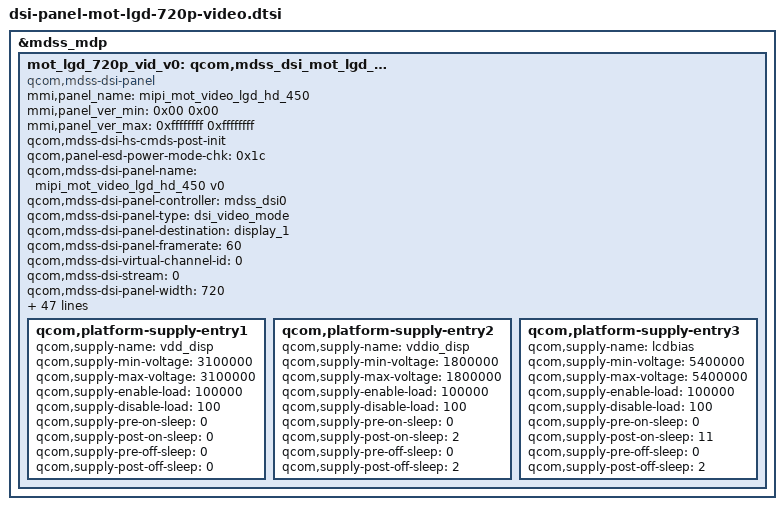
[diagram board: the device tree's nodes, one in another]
/* Copyright (c) 2013, Motorola Mobility LLC. All rights reserved.
 *
 * This program is free software; you can redistribute it and/or modify
 * it under the terms of the GNU General Public License version 2 and
 * only version 2 as published by the Free Software Foundation.
 *
 * This program is distributed in the hope that it will be useful,
 * but WITHOUT ANY WARRANTY; without even the implied warranty of
 * MERCHANTABILITY or FITNESS FOR A PARTICULAR PURPOSE.  See the
 * GNU General Public License for more details.
 */

&mdss_mdp {
	mot_lgd_720p_vid_v0: qcom,mdss_dsi_mot_lgd_720p_video_v0 {
		compatible = "qcom,mdss-dsi-panel";
		status = "ok";

		mmi,panel_name = "mipi_mot_video_lgd_hd_450";
		mmi,panel_ver_min = <0x00 0x00>;
		mmi,panel_ver_max = <0xffffffff 0xffffffff>;
		qcom,mdss-dsi-hs-cmds-post-init;
		qcom,panel-esd-power-mode-chk = <0x1c>;

		qcom,mdss-dsi-panel-name = "mipi_mot_video_lgd_hd_450 v0";
		qcom,mdss-dsi-panel-controller = <&mdss_dsi0>;
		qcom,mdss-dsi-panel-type = "dsi_video_mode";
		qcom,mdss-dsi-panel-destination = "display_1";
		qcom,mdss-dsi-panel-framerate = <60>;
		qcom,mdss-dsi-virtual-channel-id = <0>;
		qcom,mdss-dsi-stream = <0>;
		qcom,mdss-dsi-panel-width = <720>;
		qcom,mdss-dsi-panel-height = <1280>;
		qcom,mdss-pan-physical-width-dimension = <56>;
		qcom,mdss-pan-physical-height-dimension = <99>;
		qcom,mdss-dsi-panel-clockrate = <797600000>;
		qcom,mdss-dsi-h-front-porch = <96>;
		qcom,mdss-dsi-h-back-porch = <96>;
		qcom,mdss-dsi-h-pulse-width = <4>;
		qcom,mdss-dsi-h-sync-skew = <0>;
		qcom,mdss-dsi-v-back-porch = <50>;
		qcom,mdss-dsi-v-front-porch = <1086>;
		qcom,mdss-dsi-v-pulse-width = <2>;
		qcom,mdss-dsi-h-left-border = <0>;
		qcom,mdss-dsi-h-right-border = <0>;
		qcom,mdss-dsi-v-top-border = <0>;
		qcom,mdss-dsi-v-bottom-border = <0>;
		qcom,mdss-dsi-bpp = <24>;
		qcom,mdss-dsi-underflow-color = <0xff>;
		qcom,mdss-dsi-border-color = <0>;
		qcom,splash-no-solid-fill;

		qcom,mdss-dsi-on-command = [
			29 01 00 00 78 00 02 11 00      /* exit sleep */
			29 01 00 00 00 00 02 b0 ac
			29 01 00 00 00 00 06 b5 47 00 80 ff ff
			39 01 00 00 00 00 09 b1 10 14 04 16 22 31 10 10
			29 01 00 00 00 00 02 51 ff      /* led_pwm1 */
			29 01 00 00 00 00 02 53 2c      /* led_pwm2 */
			29 01 00 00 00 00 02 55 00      /* led_pwm3 */
			29 01 00 00 00 00 02 29 00];    /* display on */

		qcom,mdss-dsi-off-command = [
			05 01 00 00 01 00 02 28 00     /* display off */
			05 01 00 00 78 00 02 10 00];   /* enter sleep */

		qcom,mdss-dsi-on-command-state = "dsi_lp_mode";
		qcom,mdss-dsi-off-command-state = "dsi_lp_mode";
		qcom,mdss-dsi-h-sync-pulse = <1>;
		qcom,mdss-dsi-traffic-mode = "non_burst_sync_event";
		qcom,mdss-dsi-bllp-eof-power-mode;
		qcom,mdss-dsi-bllp-power-mode;
		qcom,mdss-dsi-lane-0-state;
		qcom,mdss-dsi-lane-1-state;
		qcom,mdss-dsi-lane-2-state;
		qcom,mdss-dsi-lane-3-state;
		qcom,mdss-dsi-tx-eot-append;
		qcom,mdss-dsi-panel-timings = [e3 3e 34 00 55 52 33 40 29 03 04 00];
		qcom,mdss-dsi-t-clk-post = <0x1e>;
		qcom,mdss-dsi-t-clk-pre = <0x34>;
		qcom,mdss-dsi-bl-min-level = <1>;
		qcom,mdss-dsi-bl-max-level = <4095>;
		qcom,mdss-dsi-dma-trigger = "trigger_sw";
		qcom,mdss-dsi-mdp-trigger = "none";
		qcom,mdss-dsi-bl-pmic-control-type = "bl_ctrl_wled";

		qcom,panel-en-reset-sequence = <1 11>;
		qcom,panel-dis-reset-sequence = <0 2>;
		qcom,platform-supply-entry1 {
			qcom,supply-name = "vdd_disp";
			qcom,supply-min-voltage = <3100000>;
			qcom,supply-max-voltage = <3100000>;
			qcom,supply-enable-load = <100000>;
			qcom,supply-disable-load = <100>;
			qcom,supply-pre-on-sleep = <0>;
			qcom,supply-post-on-sleep = <0>;
			qcom,supply-pre-off-sleep = <0>;
			qcom,supply-post-off-sleep = <0>;
		};
		qcom,platform-supply-entry2 {
			qcom,supply-name = "vddio_disp";
			qcom,supply-min-voltage = <1800000>;
			qcom,supply-max-voltage = <1800000>;
			qcom,supply-enable-load = <100000>;
			qcom,supply-disable-load = <100>;
			qcom,supply-pre-on-sleep = <0>;
			qcom,supply-post-on-sleep = <2>;
			qcom,supply-pre-off-sleep = <0>;
			qcom,supply-post-off-sleep = <2>;
		};
		qcom,platform-supply-entry3 {
			qcom,supply-name = "lcdbias";
			qcom,supply-min-voltage = <5400000>;
			qcom,supply-max-voltage = <5400000>;
			qcom,supply-enable-load = <100000>;
			qcom,supply-disable-load = <100>;
			qcom,supply-pre-on-sleep = <0>;
			qcom,supply-post-on-sleep = <11>;
			qcom,supply-pre-off-sleep = <0>;
			qcom,supply-post-off-sleep = <2>;
		};
	};
};
